# psoc4hvpaspm10 register map
Vendor: Infineon Technologies; Series: PSOC4HVPASPM10; File version: 1.0
CPU: CM0PLUS r0p1, little endian, MPU, no FPU, VTOR, 2 interrupt priority bits, 32 interrupts
Registers are 32-bit, read-write, reset 0x0 unless marked. A register's access mark holds for its fields unless they carry their own. Offsets are from the block's base; [hi:lo] are bit positions; lines under a group give offsets from that group; {n}, {i} and the like mark numbered series; 'fields as' and 'values as' point back to an identical list; <NAME> marks a mode.

## PACSS (part 2 of 2) — Programmable Analog Channel Sub-System
Base 0x40300000
{0x40000+0x10000*i} ACHAN[{i}] (i=0..1) group — Analog Channel Configuration
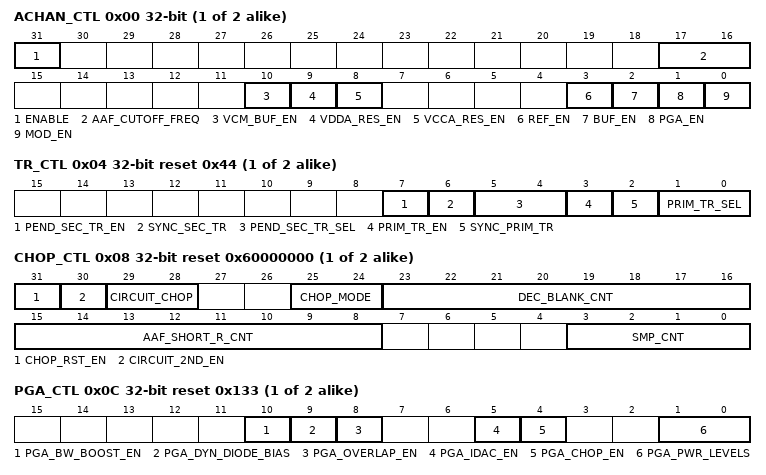
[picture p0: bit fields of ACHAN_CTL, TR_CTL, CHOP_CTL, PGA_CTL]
  0x00 ACHAN_CTL — Analog Channel Control
    [31] ENABLE — Analog Channel Enable
    [17:16] AAF_CUTOFF_FREQ
    [10] VCM_BUF_EN — VCM Buffer Enable VCM_BUF is the buffer that provides the common mode for the differential amplifiers in the modulator. It also provides input common mode to the sampling capacitor of the integrators.
    [9] VDDA_RES_EN — VDDA Resistor Reference Enable This is one of the reference options for the modulator. It is meant to be used for diagnostics.
    [8] VCCA_RES_EN — VCCA Resistor Reference Enable This is one of the options for the VCM voltage. The default is 0.8V from HPBGR. This is added for risk-mitigation.
    [3] REF_EN — Reference Enable It enables the *_SEL controls in the REF_CTL registers, which allows switch closure for the reference selection.
    [2] BUF_EN — Buffer Enable Enables the buffer, when disabled all buffer controls from BUF_CTL are disabled.
    [1] PGA_EN — Programmable Gain Amplifier Enable (also enables VNEG Pump)
    [0] MOD_EN — Modulator Enable (also enables INMUX)
  0x04 TR_CTL reset 0x44 — Trigger Control for Sequencer
    [7] PEND_SEC_TR_EN — Secondary Trigger Enable (enables HW triggers) if disabled, conversion can still be pended via user SW
    [6] SYNC_SEC_TR — Synchronize Secondary Trigger 0 - bypass clock domain synchronization of the trigger signal. 1 - synchronize the trigger signal to the DSM clock domain, if needed an edge detect is done in the peripheral clock domain. Only applicable to HW triggers
    [5:4] PEND_SEC_TR_SEL — Select for Trigger that pends secondary digital channels linked to this analog channel to convert on the next primary trigger. 0 - select HW tr_start[0] 1 - select HW tr_start[1] 2 - select HW tr_start[2] 3 - select HW tr_start[3] Only applicable to HW triggers
    [3] PRIM_TR_EN — Primary Trigger Enable (enables HW triggers) if disabled, conversion can still be started via user SW
    [2] SYNC_PRIM_TR — Synchronize Primary Trigger 0 - bypass clock domain synchronization of the trigger signal. 1 - synchronize the trigger signal to the DSM clock domain, if needed an edge detect is done in the peripheral clock domain. Only applicable to HW triggers
    [1:0] PRIM_TR_SEL — Select for Primary Trigger. Triggers starts conversion on all primary digital channels linked to this analog channel. 0 - select HW tr_start[0] 1 - select HW tr_start[1] 2 - select HW tr_start[2] 3 - select HW tr_start[3] Only applicable to HW triggers
  0x08 CHOP_CTL reset 0x60000000 — Chopping Control for Sequencer
    [31] CHOP_RST_EN
    [30] CIRCUIT_2ND_EN — 2nd Stage Circuit Chopping Enable Enables Circuit Chopping on the 2nd integrator in the modulator
    [29:28] CIRCUIT_CHOP — Circuit Chopping 0 - Off 1 - Disconnect AAF (SW1) for 1 DSM clock cycle after fchop clock edge 2 - Disconnect AAF (SW1) for 2 DSM clock cycle after fchop clock edge 3 - Disconnect AAF (SW1) for 4 DSM clock cycle after fchop clock edge Circuit chopping differs from the other fields in this register, it has no interaction with the modbit. When enabled it disconnects the AAF for the set number of clock cycles after a fchop clock edge.
    [25:24] CHOP_MODE — Chopping Mode 00 - OFF: Buffer Cross Chopping Disabled 01 - Not supported 11 - Buffer Cross Chopping Enabled 10 - Not supported Buffer cross chopping is on the input and output of the buffer using the modbit. This mode toggles the modbit when the SMP_CNT value is reached. Buffer cross chopping is only functional in the configurations where ACHAN0 is only mapped to DCHAN0, or ACHAN1 (if present) is only mapped to DCHAN1 (if present).
    [23:16] DEC_BLANK_CNT — Decimator Blanking Count Number of DSM clock cycles (DEC_BLANK_CNT) where the decimator will be disconnected from the modulator output stream, and connected to a circular FIFO of the last 32 data values after the modbit toggles
    [15:8] AAF_SHORT_R_CNT — Anti-Aliasing Filter Short Resistor Count Number of DSM clock cycles (AAF_SHORT_CNT) to short the AAF resistor after a toggle of the modbit.
    [3:0] SMP_CNT — Chopping Sample Count Number of samples to count before toggling modbit. (SMP_CNT+1). The samples counted rely only on the DR value set in DEC_CTL or SEQ_CTL. Depending on which one the Decimator is using.
  0x0C PGA_CTL reset 0x133 — Programmable Gain Amplifier Control
    [10] PGA_BW_BOOST_EN — TBD - Currently not used
    [9] PGA_DYN_DIODE_BIAS — TBD - Currently not used
    [8] PGA_OVERLAP_EN — PGA Overlap Enable Enable overlapping for the PGA chopping clocks. When disabled, PGA chopping clocks are non-overlapping
    [5] PGA_IDAC_EN — IDAC Enable
    [4] PGA_CHOP_EN — Chopping Enable
    [1:0] PGA_PWR_LEVELS — PGA Power Levels 00 - 39 percent Power Mode 01 - 58 percent Power Mode 10 - 78 percent Power Mode 11 - 100 percent Power Mode
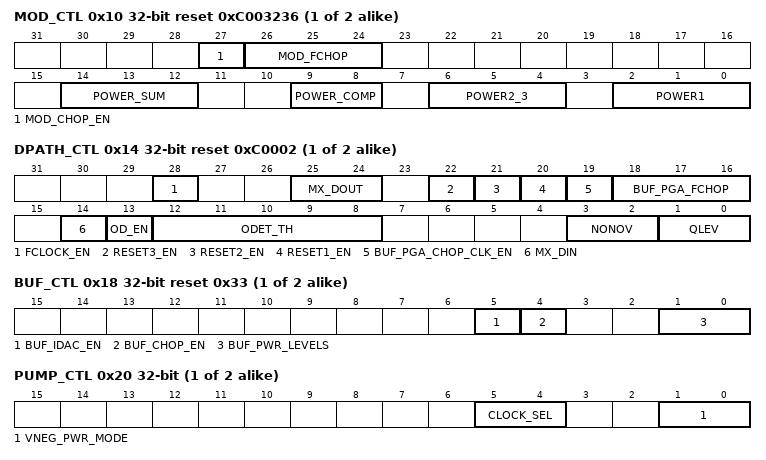
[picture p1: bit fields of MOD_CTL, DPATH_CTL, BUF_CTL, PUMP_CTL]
  0x10 MOD_CTL reset 0xC003236 — Modulator Control
    [27] MOD_CHOP_EN — Modulator Chopping Enable
    [26:24] MOD_FCHOP — Modulator Chopping Clock Frequency Selection
      0=FCLOCKDIV2 (chopping frequency is Fclock/2); 1=FCLOCKDIV4 (chopping frequency is Fclock/4); 2=FCLOCKDIV8 (chopping frequency is Fclock/8); 3=FCLOCKDIV16 (chopping frequency is Fclock/16); 4=FCLOCKDIV32 (chopping frequency is Fclock/32); 5=FCLOCKDIV64 (chopping frequency is Fclock/64); 6=FCLOCKDIV128 (chopping frequency is Fclock/128); 7=FCLOCKDIV256 (chopping frequency is Fclock/256)
    [14:12] POWER_SUM — The power control for the summer block
      0=POWER_SUM_53uA (75 percent Power Mode); 1=POWER_SUM_58uA (81 percent Power Mode); 2=POWER_SUM_67uA (94 percent Power Mode); 3=POWER_SUM_71uA (100 percent Power Mode); 4=POWER_SUM_105uA (150 percent Power Mode); 5=POWER_SUM_71uA_2 (N/A); 6=POWER_SUM_71uA_3 (N/A); 7=POWER_SUM_71uA_4 (N/A)
    [9:8] POWER_COMP — The power control for the quantizer block
      0=50 percent Power Mode; 1=75 percent Power Mode; 2=100 percent Power Mode; 3=200 percent Power Mode
    [6:4] POWER2_3 — The power control for the second and third integrator stages
      0=POWER2_3_97uA (75 percent Power Mode); 1=POWER2_3_106uA (81 percent Power Mode); 2=POWER2_3_122uA (94 percent Power Mode); 3=POWER2_3_130uA (100 percent Power Mode); 4=POWER2_3_193uA (150 percent Power Mode); 5=POWER2_3_130uA_2 (100 percent Power Mode); 6=POWER2_3_130uA_3 (100 percent Power Mode); 7=POWER2_3_130uA_4 (100 percent Power Mode)
    [2:0] POWER1 — First stage Opamp power level control
      0=POWER1_44uA (10 percent Power Mode); 1=POWER1_135uA (31 percent Power Mode); 2=POWER1_190uA (44 percent Power Mode); 3=POWER1_271uA (63 percent Power Mode); 4=POWER1_325uA (75 percent Power Mode); 5=POWER1_380uA (88 percent Power Mode); 6=POWER1_433uA (100 percent Power Mode); 7=POWER1_652uA (150 percent Power Mode)
  0x14 DPATH_CTL reset 0xC0002 — Datapath Control
    [28] FCLOCK_EN — Modulator Clock Enable (FCLOCK) By default the modulator clock only runs when converting a sample. Setting FCLOCK_CLK_EN=1 makes FCLOCK free running.
    [25:24] MX_DOUT — Select the DSM data routed to the dbg_io output: 2'h0: none 2'h1: dbg_io[5:0] = {modrst, clk_dsm_ana, dout2scomp[3:0]} 2'h2: dbg_io[5:0] = {ovdcause, ovdflag, agc_gain_lvl[3:0]} 2'h3: dbg_io[5:0] = {modrst, clk_dsm_ana, agc_gain_lvl[3:0]}
    [22] RESET3_EN — Allow third stage integrating capacitance to be reset. If enabled this reset is triggered by an overload detection
    [21] RESET2_EN — Allow second stage integrating capacitance to be reset. If enabled this reset is triggered by an overload detection
    [20] RESET1_EN — Allow first stage integrating capacitance to be reset. If enabled this reset is triggered by an overload detection
    [19] BUF_PGA_CHOP_CLK_EN — Buffer and PGA Chopping Clock enable for Buffer and PGA This bit should be set to 1 by SW in the default use case.
    [18:16] BUF_PGA_FCHOP — Chopping Clock Frequency selection for Buffer and PGA
      0=FCLOCKDIV2 (Fclock/2); 1=FCLOCKDIV4 (Fclock/4); 2=FCLOCKDIV8 (Fclock/8); 3=FCLOCKDIV16 (Fclock/16); 4=FCLOCKDIV32 (Fclock/32); 5=FCLOCKDIV64 (Fclock/64); 6=FCLOCKDIV128 (Fclock/128); 7=FCLOCKDIV256 (Fclock/256)
    [14] MX_DIN — Select the data source of the Decimator input : 0: modulator data is selected as input to decimator 1: dbg_io[3:0] is selected as the input to the decimator. In this mode dbg_io[5:4] are outputs. dbg_io[5:4]={modrst, clk_dsm_ana} Previously named DPMODE
    [13] OD_EN — Overload Detect Enable
    [12:8] ODET_TH — Overload detection threshold. If the number of continuous 1s or 0s coming out of quantizer exceeds this number, the overload detection flag is set
    [3:2] NONOV — Non-Overlap delay of clock phases 2'h0: low (1.57ns, typ) 2'h1: medium (2.54ns, typ) 2'h2: high (6.47ns, typ) 2'h3: very high (9.91ns, typ) Default is low, other settings are for risk mitigation
    [1:0] QLEV
  0x18 BUF_CTL reset 0x33 — Buffer Control
    [5] BUF_IDAC_EN — Buffer IDAC enable
    [4] BUF_CHOP_EN — Buffer chopping enable
    [1:0] BUF_PWR_LEVELS — Buffer Power Levels 00 - 32 percent Power Mode 01 - 55 percent Power Mode 10 - 78 percent Power Mode 11 - 100 percent Power Mode
  0x20 PUMP_CTL — Pump Control
    [5:4] CLOCK_SEL — Negative Pump Clock selection The negative pump requires a 24 MHz clock For bit decode use the following: 00: pump clock sourced by clk_pump/2, use if clk_pump is set to 48MHz 01: pump clock sourced by clk_pump/1, use if clk_pump is set to 24 MHz 10: pump clock sourced by clk_hf/2, use if clk_hf is set to 48 MHz 11: pump clock sourced by clk_hf/1, use if clk_hf is set to 24 MHz
    [1:0] VNEG_PWR_MODE — Negative pump power mode. Trim for risk mitigation, not intended for customer use.
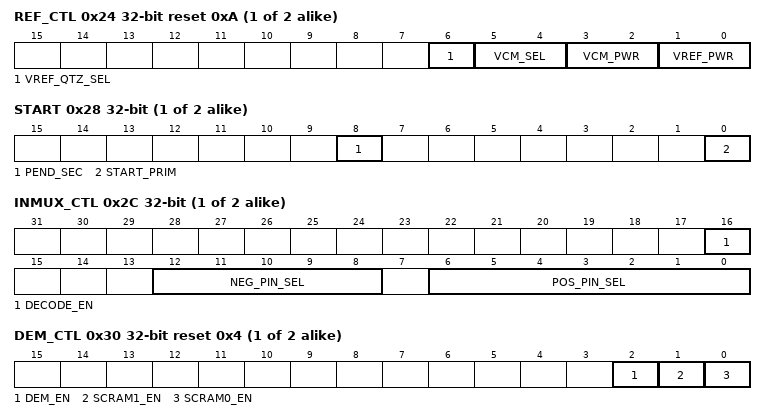
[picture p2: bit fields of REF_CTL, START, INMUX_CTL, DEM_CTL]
  0x24 REF_CTL reset 0xA — Reference Control
    [6] VREF_QTZ_SEL — VREF_QTZ selection 0 - VREFH CDAC 1 - VCCA_KELVIN
    [5:4] VCM_SEL
    [3:2] VCM_PWR — Power Control for the Voltage Common Mode Buffer for the Sigma Delta ADC
      0=VCM_18uA (VCM Buffer is operating in Low Power (18 uA) mode); 1=VCM_28uA (VCM Buffer is operating in Medium Power (28 uA) mode); 2=VCM_55uA (VCM Buffer is operating in High Power (55 uA) mode); 3=VCM_114uA (VCM Buffer is operating in Turbo Power (114 uA) mode)
    [1:0] VREF_PWR — Power control for the voltage reference buffer for the sigma delta ADC
      0=VREF_26uA (VREF Buffer is operating in Low Power (26 uA) mode); 1=VREF_32uA (VREF Buffer is operating in Medium Power (32 uA) mode); 2=VREF_118uA (VREF Buffer is operating in High Power (118 uA) mode); 3=VREF_232uA (VREF Buffer is operating in Turbo Power (232 uA) mode)
  0x28 START — Start Conversion
    [8] PEND_SEC write-1-sets — Pend Secondary Conversion (FW Trigger) A write of 1 to this bit pends a secondary conversion. This bit is cleared after the next primary conversion completes.
    [0] START_PRIM write-1-sets — Start Primary Conversion (FW Trigger) . A write of 1 to this bit starts a primary conversion. This bit is cleared once the conversion is started. A write of 1 while the sequencer is busy is ignored and the FWT_COLLISION interrupt is set for the digital channels assigned to this sequencer.
  0x2C INMUX_CTL — INMUX Control
    [16] DECODE_EN — Enables Decode Logic to close switches. This must be set to '1' allow usage of POS_PIN_SEL and NEG_PIN_SEL. If set to '0' all switches in the INMUX will be open. This register is only applicable when SWITCH_SQ_CTL.INMUX=0
    [12:8] NEG_PIN_SEL — Negative Pin Select This register is only functional when the sequencer control of the INMUX is disabled. See SWITCH_SQ_CTL.INMUX. This register is the manual (non-sequencer) configuration of INMUX negative pin selection.
      0=NEG_PIN_SEL_VSSA (0x00 - vssa); 8=NEG_PIN_SEL_VSSA_K0 (0x08 - vssa_k0, unused (floating)); 9=NEG_PIN_SEL_VSSA_K1 (0x09 - vssa_k1, vrefl); 10=NEG_PIN_SEL_VSSA_K2 (0x0A - vssa_k2, srss_vss); 11=NEG_PIN_SEL_VSSA_K3 (0x0B - vssa_k3, vdiv_ret); 12=NEG_PIN_SEL_VSSA_K4 (0x0C - vssa_k4, vts_ret); 13=NEG_PIN_SEL_VSSA_K5 (0x0D - vssa_k5, vtint_ret); 14=NEG_PIN_SEL_VSSA_K6 (0x0E - vssa_k6, gpio0); 15=NEG_PIN_SEL_VSSA_K7 (0x0F - vssa_k7, gpio2); 16=NEG_PIN_SEL_RSL0 (0x10 - rsl0); 24=NEG_PIN_SEL_RSL1 (0x18 - rsl1)
    [6:0] POS_PIN_SEL — Positive Pin Select This register is only functional when the sequencer control of the INMUX is disabled. See SWITCH_SQ_CTL.INMUX. This register is the manual (non-sequencer) configuration of INMUX positive pin selection.
  0x30 DEM_CTL reset 0x4 — Dynamic Element Matching Control
    [2] DEM_EN — Enable DEM Bi-directional Data Weighted Averaging (DWA) based Dynamic Element Matching (DEM) scheme for mismatch cancellation. Bi-directional DWA alters the direction of pointers used for rotation every cycle for avoiding repetition pattern of the DWA for low value DC inputs. DWA mode: SCRAM0_EN=0, SCRAM1_EN=0 Alternate DWA mode (not preferred): SCRAM0_EN=1, SCRAM1_EN=0 Bi-DWA mode: SCRAM0_EN=0, SCRAM1_EN=1 Not used: SCRAM0_EN=1, SCRAM1_EN=1
    [1] SCRAM1_EN — Enable Scrambler 1 Also known as EN_BIDWA
    [0] SCRAM0_EN — Enable Scrambler 0 Also known as EN_ADWA
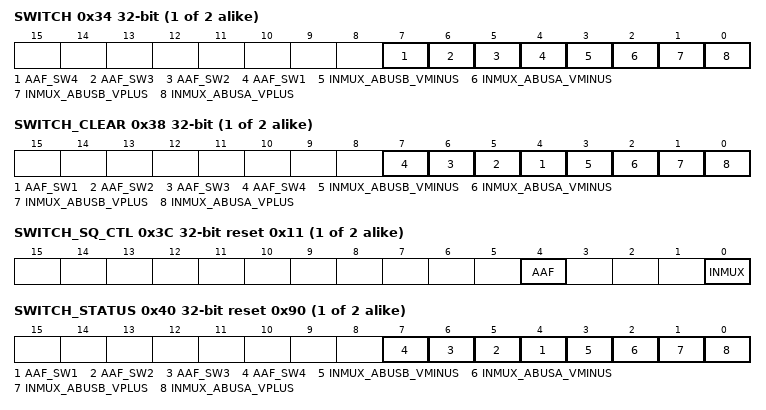
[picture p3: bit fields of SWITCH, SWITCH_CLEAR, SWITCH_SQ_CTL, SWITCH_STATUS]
  0x34 SWITCH — Firmware Switch Control
    [7] AAF_SW4 write-1-sets — Firmware control: 0=open, 1=close AAF switch 4. Write with '1' to set bit. This switch can only be closed via this register if SWITCH_SQ_CTL.AAF=0
    [6] AAF_SW3 write-1-sets — Firmware control: 0=open, 1=close AAF switch 3. Write with '1' to set bit. This switch can only be closed via this register if SWITCH_SQ_CTL.AAF=0.
    [5] AAF_SW2 write-1-sets — Firmware control: 0=open, 1=close AAF switch 2. Write with '1' to set bit. This switch can only be closed via this register if SWITCH_SQ_CTL.AAF=0
    [4] AAF_SW1 write-1-sets — Firmware control: 0=open, 1=close AAF switch 1. Write with '1' to set bit. This switch can only be closed via this register if SWITCH_SQ_CTL.AAF=0
    [3] INMUX_ABUSB_VMINUS write-1-sets — Firmware control: 0=open, 1=close switch between VMINUS and AMUXBUSB. Write with '1' to set bit. This switch can be closed while the sequencer is controls the INMUX pin selection
    [2] INMUX_ABUSA_VMINUS write-1-sets — Firmware control: 0=open, 1=close switch between VMINUS and AMUXBUSA output. Write with '1' to set bit. This switch can be closed while the sequencer is controls the INMUX pin selection
    [1] INMUX_ABUSB_VPLUS write-1-sets — Firmware control: 0=open, 1=close switch between VPLUS and AMUXBUSB. Write with '1' to set bit. This switch can be closed while the sequencer is controls the INMUX pin selection
    [0] INMUX_ABUSA_VPLUS write-1-sets — Firmware control: 0=open, 1=close switch between VPLUS and AMUXBUSA output. Write with '1' to set bit. This switch can be closed while the sequencer is controls the INMUX pin selection
  0x38 SWITCH_CLEAR — Firmware Switch Control Clear
    [n+3] AAF_SW{n} write-1-clears (n=1..4) — Write '1' to clear corresponding bit in the SWITCH register
    [3] INMUX_ABUSB_VMINUS write-1-clears — Write '1' to clear corresponding bit in the SWITCH register
    [2] INMUX_ABUSA_VMINUS write-1-clears — Write '1' to clear corresponding bit in the SWITCH register
    [1] INMUX_ABUSB_VPLUS write-1-clears — Write '1' to clear corresponding bit in the SWITCH register
    [0] INMUX_ABUSA_VPLUS write-1-clears — Write '1' to clear corresponding bit in the SWITCH register
  0x3C SWITCH_SQ_CTL reset 0x11 — Switch Sequencer Control
    [4] AAF — Allow sequencer control for the provided switches
    [0] INMUX — Allow sequencer control for the provided switches
  0x40 SWITCH_STATUS ro reset 0x90
    [n+3] AAF_SW{n} (n=1..4) — switch status of corresponding bit in the SWITCH register
    [3] INMUX_ABUSB_VMINUS — switch status of corresponding bit in the SWITCH register
    [2] INMUX_ABUSA_VMINUS — switch status of corresponding bit in the SWITCH register
    [1] INMUX_ABUSB_VPLUS — switch status of corresponding bit in the SWITCH register
    [0] INMUX_ABUSA_VPLUS — switch status of corresponding bit in the SWITCH register
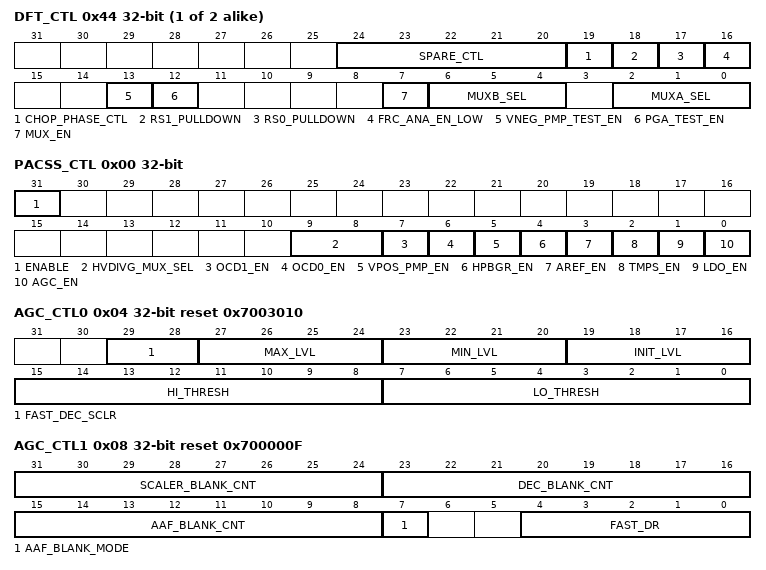
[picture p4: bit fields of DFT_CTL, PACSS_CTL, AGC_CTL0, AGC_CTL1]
  0x44 DFT_CTL — DFT Control Register
    [24:20] SPARE_CTL — Spare MMIO Controls for analog
    [19] CHOP_PHASE_CTL — Circuit chopping phase control. Inverts circuit chopping phase
    [18] RS1_PULLDOWN — RS1 Pull-down. Enables pull down on RSH1/RSL1 input pair for offset calibration.
    [17] RS0_PULLDOWN — RS0 Pull-down. Enables pull down on RSH0/RSL0 input pair for offset calibration.
    [16] FRC_ANA_EN_LOW — Force global analog enable low (enable_scanoff_hv) to test for any SA1 faults on the level-shifter enables.
    [13] VNEG_PMP_TEST_EN — Negative Pump Test Enable
    [12] PGA_TEST_EN — PGA Test Mode
    [7] MUX_EN — DFT MUX Enable
    [6:4] MUXB_SEL — DFT MUX Selection for AMUXBUSB
      0=VCCA_DSM_DFT (dft_out = vcca_dsm_dft); 1=REFOUT (dft_out = refout); 2=VREF_QTZ (dft_out = vref_qtz); 3=AAF_IN_N (dft_out = aaf_in_n); 4=IREF_2P4U (dft_out = iref_2p4u - current source of buffer top amp cascode device); 5=BUFFIN_VMINUS (dft_out = buffin_vminus); 6=BUFFIN_VPLUS (dft_out = buffin_vplus); 7=BUFOUT_VMINUS (dft_out = bufout_vminus)
    [2:0] MUXA_SEL — DFT MUX Selection for AMUXBUSA
      0=VCCA_DSM_DFT_KELVIN (dft_out = vcca_dsm_dft_kelvin); 1=VCM (dft_out = vcm); 2=VREF_DAC (dft_out = vref_dac); 3=AAF_IN_P (dft_out = aaf_in_p); 4=IREF_4P8U (dft_out = iref_4p8u - current source of PGA top amp cascode device); 5=BUFFIN_VPLUS (dft_out = buffin_vplus); 6=BUFFIN_VMINUS (dft_out = buffin_vminus); 7=BUFOUT_VPLUS (dft_out = bufout_vplus)
  0x48 DFT_STATUS ro
    [0] OBSVR_LS_OUT — Observation point of level-shifters output. Used for detection of SA1 faults on the level-shifter enables. The read back value of this register changes based on the configuration and trims of the ACHAN and PACSS_MMIO registers.
  0xFF00 TRIM_PGA0_CTL — PGA Trim 0 (lock protected)
    [5:0] OFST_P — Offset Plus Trim
  0xFF04 TRIM_PGA1_CTL — PGA Trim 1 (lock protected)
    [5:0] OFST_SLOPE_P — Offset Slope Plus Trim
  0xFF08 TRIM_PGA2_CTL — PGA Trim 2 (lock protected)
    [5:0] OFST_M — Offset Minus Trim
  0xFF0C TRIM_PGA3_CTL — PGA Trim 3 (lock protected)
    [5:0] OFST_SLOPE_M — Offset Slope Minus Trim
  0xFF10 TRIM_PGA4_CTL reset 0x4 — PGA Trim 4 (lock protected)
    [2:0] CM — Common Mode (Output Range) Trim
  0xFF14 TRIM_BUF0_CTL — Buffer Trim 0 (lock protected)
    [5:0] OFST_P — Offset Plus Trim
  0xFF18 TRIM_BUF1_CTL — Buffer Trim 1 (lock protected)
    [5:0] OFST_PTAT_P — Offset PTAT Plus Trim
  0xFF1C TRIM_BUF2_CTL — Buffer Trim 2 (lock protected)
    [5:0] OFST_M — Offset Minus Trim
  0xFF20 TRIM_BUF3_CTL — Buffer Trim 3 (lock protected)
    [5:0] OFST_PTAT_M — Offset PTAT Minus Trim
0xF0000 MMIO group — PACSS Global MMIO
  0x00 PACSS_CTL — Precision Analog Channel Control
    [31] ENABLE — Global Enable
    [9:8] HVDIVG_MUX_SEL — High Voltage Divider Ground Reference Mux Select 0 - Select VSSA 1 - Select VSSA 2 - Select RSH[0] 3 - Select RSL[0] This field is not applicable if VDIAG pin is not a package pin, in which case the selection is forced to VSSA regardless of how this field is set.
    [7] OCD1_EN — Over Current Detection 1 Enable
    [6] OCD0_EN — Over Current Detection 0 Enable
    [5] VPOS_PMP_EN — Positive Pump Enable
    [4] HPBGR_EN — High Precision Bandgap Reference Enable
    [3] AREF_EN — AREF Enable
    [2] TMPS_EN — Temperature Sensor Enable
    [1] LDO_EN — Low Dropout Regulator Enable Enables modulator voltage supply
    [0] AGC_EN — Auto-Gain Correction Enable
  0x04 AGC_CTL0 reset 0x7003010 — Auto-Gain Correction Control 0
    [29:28] FAST_DEC_SCLR — Fast Decimator Scaler Used to apply digital gain to output of the AGC's fast decimator. Intended to be used when digital gain is applied to the system via moving sum. 0 : FAST_DEC_RESULT = RESULT 1 : FAST_DEC_RESULT = RESULT << 1 2 : FAST_DEC_RESULT = RESULT << 2 3 : FAST_DEC_RESULT = RESULT << 3
    [27:24] MAX_LVL — Maximum Gain level The maximum gain level that the AGC is allowed to reach when incrementing Acceptable values are 0 - 9, but MIN_LVL <= INIT_LVL <= MAX_LVL
    [23:20] MIN_LVL — Minimum Gain Level The minimum gain level the AGC is allowed to reach when decrementing. Acceptable values are 0 - 9, but MIN_LVL <= INIT_LVL <= MAX_LVL
    [19:16] INIT_LVL — Initial Gain level The gain level that the AGC is initialized to once a conversion starts. Acceptable values are 0 - 9.
    [15:8] HI_THRESH — High Threshold value Magnitude of high threshold value. This is an absolute value comparison. If the fast decimator result is higher than this threshold value, the gain level will be decremented. Gain levels must be configured from lowest to highest gain. modulator output ranges from -4 to 4. The max value will be 4* (FAST_DR+1) Based on default values: 4*16 = 64, default is 75 percent (48=0x30) Ex: set 0x64 to set to -100 (decimal) or 100 (decimal)
    [7:0] LO_THRESH — Low Threshold value Magnitude of lower threshold value. This is an absolute value comparison. If the fast decimator result is lower than this threshold value, the gain level will be incremented. Gain levels must be configured from lowest to highest gain. modulator output ranges from -4 to 4. The max value will be 4* (FAST_DR+1) Based on default values: 4*16 = 64, default is 25 percent (16=0x10) Ex: set to 0x20 to set to -32 (decimal) or 32 (decimal)
  0x08 AGC_CTL1 reset 0x700000F — Auto-Gain Correction Control 1
    [31:24] SCALER_BLANK_CNT — Scaler Blank Count Number of DSM clock cycles (SCALER_BLANKT_CNT) where the gain scaler of next gain level will be delayed after a gain level change. The scaler will use its previous value until this count value is reached.
    [23:16] DEC_BLANK_CNT — Decimator Blank Count Number of DSM clock cycles (DEC_BLANK_CNT) where the decimator will be disconnected from the modulator output stream, and connected to a circular FIFO of the last 32 data values after a gain level change.
    [15:8] AAF_BLANK_CNT — AAF Blank Count Number of DSM clock cycles (AAF_BLANK_CNT) where the AAF will either be shorted or disconnected after a gain level change.
    [7] AAF_BLANK_MODE — Anti-Aliasing Filter (AAF) Blanking Mode 0 - Short AAF resistor (close SW2) 1 - Bypass AAF (open SW1) Shorting the AAF reduces the settling time
    [4:0] FAST_DR — Fast Decimator Decimation Ratio (FAST_DR+1) sets the decimation ratio for the AGC's Fast Decimator The fast decimator will run continuously with this FAST_DR value while the DCHAN0 decimator is running.
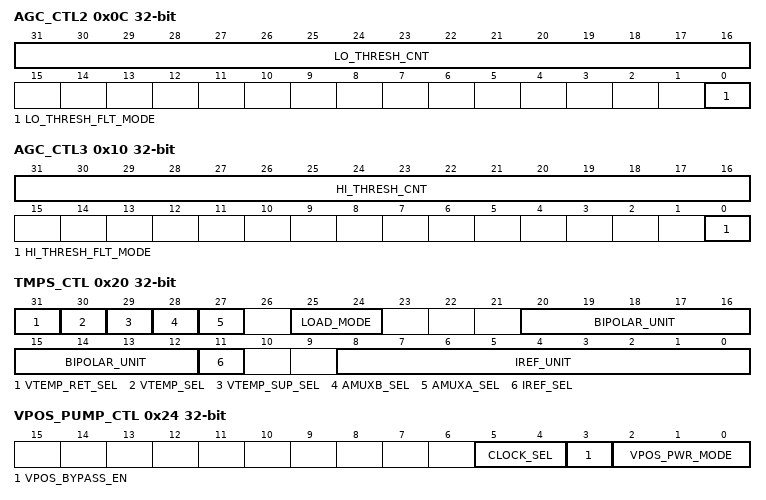
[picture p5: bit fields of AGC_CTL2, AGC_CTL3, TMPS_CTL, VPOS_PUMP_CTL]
  0x0C AGC_CTL2 — Auto-Gain Correction Control 2
    [31:16] LO_THRESH_CNT — Low Threshold Filter Counter LO_THRESH_CNT + 1, is the count value used for filtering the next gain level change.
    [0] LO_THRESH_FLT_MODE — Low Threshold Filter Mode 0 - counter mode 1 - integrator mode
  0x10 AGC_CTL3 — Auto-Gain Correction Control 3
    [31:16] HI_THRESH_CNT — High Threshold Filter Counter HI_THRESH_CNT + 1, is the count value used for filtering the next gain level change.
    [0] HI_THRESH_FLT_MODE — High Threshold Filter Mode 0 - counter mode 1 - integrator mode
  0x20 TMPS_CTL — Temperature Sensor Control
    [31] VTEMP_RET_SEL — Connect VTEMP_RET pin to the vssa_kelvin of the BJTs and resistor.
    [30] VTEMP_SEL — Connect VTEMP pin to vbe/vres output voltage.
    [29] VTEMP_SUP_SEL — Select external current source to bias the BJTs or Resistor.
    [28] AMUXB_SEL — Select amuxbus_b to be connected to temp sensor vbe/vres output.
    [27] AMUXA_SEL — Select amuxbus_a as a current source for biasing BJTs or Resistor
    [25:24] LOAD_MODE
    [20:12] BIPOLAR_UNIT — Number of bipolar transistors, between 0 (all switches open) and 9 Each bit set of BIPOLAR_UNIT, adds a BIPOLAR transistors Only applicable for PNP and NPN load modes
    [11] IREF_SEL — Temperature Sensor Current Reference Select Select between SRSS and AREF current reference 0 - selects AREF as current reference source 1 - selects SRSS as current reference source
    [8:0] IREF_UNIT — Number of units, between 0 (all switches open) and 9 IREF current = 9.6uA * (# of bits set) Each bit set of IREF_UNIT adds a multiple of 9.6uA.
  0x24 VPOS_PUMP_CTL — Positive Pump Control
    [5:4] CLOCK_SEL — Positive Pump Clock selection The positive pump requires a 24 MHz clock For bit decode use the following: 00: pump clock sourced by clk_pump/2, use if clk_pump is set to 48MHz 01: pump clock sourced by clk_pump/1, use if clk_pump is set to 24 MHz 10: pump clock sourced by clk_hf/2, use if clk_hf is set to 48 MHz 11: pump clock sourced by clk_hf/1, use if clk_hf is set to 24 MHz
    [3] VPOS_BYPASS_EN
    [2:0] VPOS_PWR_MODE
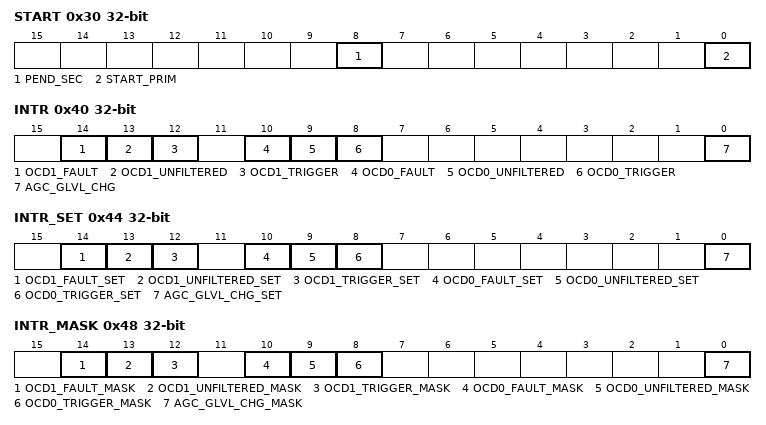
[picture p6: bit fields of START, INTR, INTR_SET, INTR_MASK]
  0x30 START — Start Conversion
    [8] PEND_SEC write-1-sets — Pend Secondary Conversion (FW Trigger) A write of 1 to this bit pends a secondary conversion. This bit is cleared after the next primary conversion completes.
    [0] START_PRIM write-1-sets — Start Primary Conversion (FW Trigger) . A write of 1 to this bit starts a primary conversion on both sequencers simultaneously. This bit is cleared once the conversion is started. A write of 1 while the sequencer(s) is busy is ignored and the FWT_COLLISION interrupt is set for the digital channels assigned to sequencer(s) that are busy.
  0x40 INTR — System Interrupt request register
    [14] OCD1_FAULT write-1-clears — Over Current Detection 1 Fault Interrupt Hardware sets this interrupt when there is a fault in the Over Current Detection Glitch Filter as defined in tables 4 and 5 in BROS . Write with '1' to clear bit.
    [13] OCD1_UNFILTERED write-1-clears — Over Current Detection 1 Unfiltered Interrupt Hardware sets this interrupt when either ocd_pos_out or ocd_neg_out is asserted. Write with '1' to clear bit.
    [12] OCD1_TRIGGER write-1-clears — Over Current Detection 1 Trigger Interrupt Hardware sets this interrupt when an over current detection trigger occurs. Write with '1' to clear bit.
    [10] OCD0_FAULT write-1-clears — Over Current Detection 0 Fault Interrupt Hardware sets this interrupt when there is a fault in the Over Current Detection Glitch Filter as defined in tables 4 and 5 in BROS . Write with '1' to clear bit.
    [9] OCD0_UNFILTERED write-1-clears — Over Current Detection 0 Unfiltered Interrupt Hardware sets this interrupt when either ocd_pos_out or ocd_neg_out is asserted. Write with '1' to clear bit.
    [8] OCD0_TRIGGER write-1-clears — Over Current Detection 0 Trigger Interrupt Hardware sets this interrupt when an over current detection trigger occurs. Write with '1' to clear bit.
    [0] AGC_GLVL_CHG write-1-clears — AGC Gain Level Change Interrupt Hardware sets this interrupt when a gain level change occurs. Write with '1' to clear bit.
  0x44 INTR_SET — System Interrupt set request register
    [14] OCD1_FAULT_SET write-1-sets — Write with '1' to set corresponding bit in interrupt request register.
    [13] OCD1_UNFILTERED_SET write-1-sets — Write with '1' to set corresponding bit in interrupt request register.
    [12] OCD1_TRIGGER_SET write-1-sets — Write with '1' to set corresponding bit in interrupt request register.
    [10] OCD0_FAULT_SET write-1-sets — Write with '1' to set corresponding bit in interrupt request register.
    [9] OCD0_UNFILTERED_SET write-1-sets — Write with '1' to set corresponding bit in interrupt request register.
    [8] OCD0_TRIGGER_SET write-1-sets — Write with '1' to set corresponding bit in interrupt request register.
    [0] AGC_GLVL_CHG_SET write-1-sets — Write with '1' to set corresponding bit in interrupt request register.
  0x48 INTR_MASK — System Interrupt mask register
    [14] OCD1_FAULT_MASK — Mask bit for corresponding bit in interrupt request register.
    [13] OCD1_UNFILTERED_MASK — Mask bit for corresponding bit in interrupt request register.
    [12] OCD1_TRIGGER_MASK — Mask bit for corresponding bit in interrupt request register.
    [10] OCD0_FAULT_MASK — Mask bit for corresponding bit in interrupt request register.
    [9] OCD0_UNFILTERED_MASK — Mask bit for corresponding bit in interrupt request register.
    [8] OCD0_TRIGGER_MASK — Mask bit for corresponding bit in interrupt request register.
    [0] AGC_GLVL_CHG_MASK — Mask bit for corresponding bit in interrupt request register.
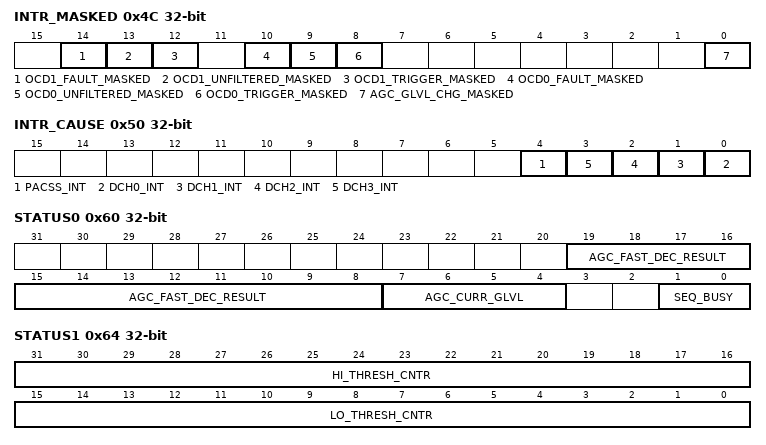
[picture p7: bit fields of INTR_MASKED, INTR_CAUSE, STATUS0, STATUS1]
  0x4C INTR_MASKED ro — System Interrupt masked request register
    [14] OCD1_FAULT_MASKED — Logical and of corresponding request and mask bits.
    [13] OCD1_UNFILTERED_MASKED — Logical and of corresponding request and mask bits.
    [12] OCD1_TRIGGER_MASKED — Logical and of corresponding request and mask bits.
    [10] OCD0_FAULT_MASKED — Logical and of corresponding request and mask bits.
    [9] OCD0_UNFILTERED_MASKED — Logical and of corresponding request and mask bits.
    [8] OCD0_TRIGGER_MASKED — Logical and of corresponding request and mask bits.
    [0] AGC_GLVL_CHG_MASKED — Logical and of corresponding request and mask bits.
  0x50 INTR_CAUSE ro — Interrupt Cause Register
    [4] PACSS_INT — System (PACSS_MMIO) Interrupt Pending
    [n] DCH{n}_INT (n=0..3) — Digital Channel {n} Interrupt Pending
  0x60 STATUS0 ro — Status Register 0
    [19:8] AGC_FAST_DEC_RESULT — AGC Fast Decimator Result
    [7:4] AGC_CURR_GLVL — AGC Current gain level
    [1:0] SEQ_BUSY — Sequencer Busy, bit per analog channel
  0x64 STATUS1 ro — Status Register 1
    [31:16] HI_THRESH_CNTR — Status of High threshold counter
    [15:0] LO_THRESH_CNTR — Status of Low threshold counter
  {0x100+0x10*j} GAINLVL_STRUCT[{j}] (j=0..9) group — Gain Level Configuration
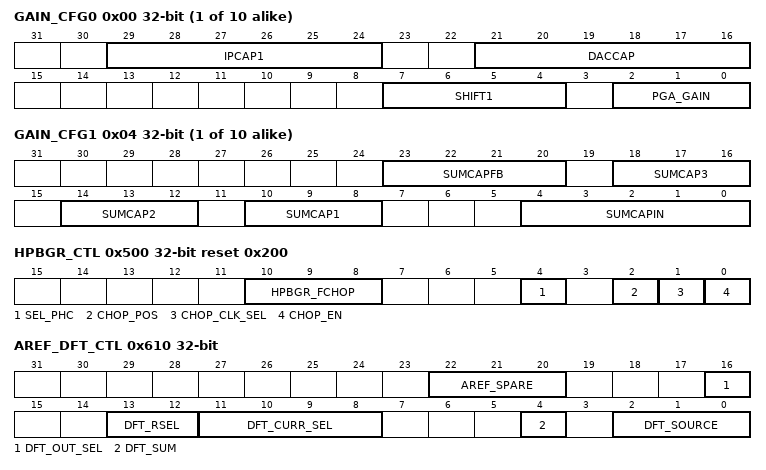
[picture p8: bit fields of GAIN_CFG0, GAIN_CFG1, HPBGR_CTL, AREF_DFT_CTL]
    0x00 GAIN_CFG0 — Gain configuration register 0
      [29:24] IPCAP1 — Binary weighted first stage integrating capacitance
        0=IPCAP1_min (Min Value = 100 fF); 63=IPCAP1_max (Max Value = 6.4 pF); 1=IPCAP1_100fF (IPCAP1[0] set -> +100 fF); 2=IPCAP1_200fF (IPCAP1[1] set -> +200 fF); 4=IPCAP1_400fF (IPCAP1[2] set -> +400 fF); 8=IPCAP1_80fF (IPCAP1[3] set -> +800 fF); 16=IPCAP1_1600fF (IPCAP1[4] set -> +1600 fF); 32=IPCAP1_3200fF (IPCAP1[5] set -> +3200 fF)
      [21:16] DACCAP — Binary weighted first stage DAC capacitance
        0=DACCAP_min (Min Value = 96 fF); 63=DACCAP_max (Max Value = 6.4 pF); 1=DACCAP_96fF (DACCAP[0] set -> add 12*8= +96 fF); 2=DACCAP_192fF (DACCAP[1] set -> add 24*8= +192 fF); 4=DACCAP_400fF (DACCAP[2] set -> add 50*8= +400 fF); 8=DACCAP_800fF (DACCAP[3] set -> add 100*8= +800 fF); 16=DACCAP_1600fF (DACCAP[4] set -> add 200*8= +1600 fF); 32=DACCAP_3200fF (DACCAP[5] set -> add 400*8= +3200 fF)
      [7:4] SHIFT1 — Value for left shift amount (see SHIFTL in DEC_CTL)
      [2:0] PGA_GAIN — Gain setting of 1,2,4,8,16, 32 are supported
        0=GAIN_1X (1x); 1=GAIN_2X (2x); 2=GAIN_4X (4x); 3=GAIN_8X (8x); 4=GAIN_16X (16x); 5=GAIN_32X (32x)
    0x04 GAIN_CFG1 — Gain configuration register 1
      [23:20] SUMCAPFB — The summer feedback capacitance
        0=SUMCAPFB_50fF (50fF); 1=SUMCAPFB_100fF (100fF); 2=SUMCAPFB_150fF (150fF); 3=SUMCAPFB_200fF (200fF); 4=SUMCAPFB_250fF (250fF); 5=SUMCAPFB_300fF (300fF); 6=SUMCAPFB_350fF (350fF); 7=SUMCAPFB_400fF (400fF); 8=SUMCAPFB_450fF (450fF); 9=SUMCAPFB_500fF (500fF); 10=SUMCAPFB_550fF (550fF); 11=SUMCAPFB_600fF (600fF); 12=SUMCAPFB_650fF (650fF); 13=SUMCAPFB_700fF (700fF); 14=SUMCAPFB_750fF (750fF); 15=SUMCAPFB_800fF (800fF)
      [18:16] SUMCAP3 — The summer capacitance that lies on the feed-forward path from the third integrator output
        0=SUMCAP3_50fF (50fF); 1=SUMCAP3_100fF (100fF); 2=SUMCAP3_150fF (150fF); 3=SUMCAP3_200fF (200fF); 4=SUMCAP3_250fF (250fF); 5=SUMCAP3_300fF (300fF); 6=SUMCAP3_350fF (350fF); 7=SUMCAP3_400fF (400fF)
      [14:12] SUMCAP2 — The summer capacitance that lies on the feed-forward path from the second integrator output
        0=SUMCAP2_50fF (50fF); 1=SUMCAP2_100fF (100fF); 2=SUMCAP2_150fF (150fF); 3=SUMCAP2_200fF (200fF); 4=SUMCAP2_250fF (250fF); 5=SUMCAP2_300fF (300fF); 6=SUMCAP2_350fF (350fF); 7=SUMCAP2_400fF (400fF)
      [10:8] SUMCAP1 — The summer capacitance that lies on the feed-forward path from the first integrator output
        0=SUMCAP1_50fF (50fF); 1=SUMCAP1_100fF (100fF); 2=SUMCAP1_150fF (150fF); 3=SUMCAP1_200fF (200fF); 4=SUMCAP1_250fF (250fF); 5=SUMCAP1_300fF (300fF); 6=SUMCAP1_350fF (350fF); 7=SUMCAP1_400fF (400fF)
      [4:0] SUMCAPIN — The summer capacitance that lies on the path where the input signal is summed
        0=SUMCAPIN_50fF (50fF); 1=SUMCAPIN_100fF (100fF); 2=SUMCAPIN_150fF (150fF); 3=SUMCAPIN_200fF (200fF); 4=SUMCAPIN_250fF (250fF); 5=SUMCAPIN_300fF (300fF); 6=SUMCAPIN_350fF (350fF); 7=SUMCAPIN_400fF (400fF); 8=SUMCAPIN_450fF (450fF); 9=SUMCAPIN_500fF (500fF); 10=SUMCAPIN_550fF (550fF); 11=SUMCAPIN_600fF (600fF); 12=SUMCAPIN_650fF (650fF); 13=SUMCAPIN_700fF (700fF); 14=SUMCAPIN_750fF (750fF); 15=SUMCAPIN_800fF (800fF); 16=SUMCAPIN_850fF (850fF); 17=SUMCAPIN_900fF (900fF); 18=SUMCAPIN_950fF (950fF); 19=SUMCAPIN_1000fF (1000fF); 20=SUMCAPIN_1050fF (1050fF); 21=SUMCAPIN_1100fF (1100fF); 22=SUMCAPIN_1150fF (1150fF); 23=SUMCAPIN_1200fF (1200fF); 24=SUMCAPIN_1250fF (1250fF); 25=SUMCAPIN_1300fF (1300fF); 26=SUMCAPIN_1350fF (1350fF); 27=SUMCAPIN_1400fF (1400fF); 28=SUMCAPIN_1450fF (1450fF); 29=SUMCAPIN_1500fF (1500fF); 30=SUMCAPIN_1550fF (1550fF); 31=SUMCAPIN_1600fF (1600fF)
    0x08 OFST_COR — Offset Correction register
      [15:0] OCOR — Decimator Offset Correction Coefficient See DCHAN.OCOR_COR for description details
    0x0C GAIN_COR — Gain Correction register
      [15:0] GCOR — Decimator Gain Correction Coefficient See DCHAN.GAIN_COR for description details
  0x500 HPBGR_CTL reset 0x200 — High Precision Bandgap Reference Control
    [10:8] HPBGR_FCHOP — High Precision Bandgap Reference Chopping Clock Frequency selection
      values as ACHAN[0].DPATH_CTL.BUF_PGA_FCHOP
    [4] SEL_PHC — Buffer phase compensation option for external capacitor (0: cap present, 1: cap absent)
    [2] CHOP_POS — Chopping position select (0: normal phase, 1: reverse phase. Applies to output buffer and BGR core; BGR core is also affected by CHOP_CLK_SEL). Only applies when CHOP_EN=0.
    [1] CHOP_CLK_SEL — Bgr core chopping phase select input (0: normal phase, 1: reverse phase)
    [0] CHOP_EN — HPBGR Chopping Enable (1: enable, 0: disable) ACHAN0 must be enabled, along with ACHAN0.ACHAN_CTL.MOD_EN for this bit to take affect. Setting this bit also enables a free running clock to the ACHAN0's modulator. This bit should be set to 1 by SW in the default use case.
  0x510 HPBGR_DFT_CTL — High Precision Bandgap Reference DFT Control
    [2:0] ADFT_MODE
  0x600 AREF_CTL — Analog Reference Control
    [0] LP_MODE — Low Power Mode 0 - Full power, all currents available 1 - No 2.4uA currents available, others are available AREF automatically enters low power mode when the device is DeepSleep, this bit can be used to enter low power mode when the device is in Active mode.
  0x610 AREF_DFT_CTL — Analog Reference DFT Control
    [22:20] AREF_SPARE
    [16] DFT_OUT_SEL — ADFT output select (0: to amuxbusa, 1: to amuxbusb)
    [13:12] DFT_RSEL — DFT Resistor Select For applying an internal pulldown resistor on the current output to amuxbus. When the pulldown is activated, both amuxbus_a and amuxbus_b connect to the resistor, allowing for kelvin connection to measure the resistor. 0 - No resistor (current output only) 1 - 10k resistor pulldown 2 - 200k resistor pulldown 3 - 1.2M resistor pulldown
    [11:8] DFT_CURR_SEL — Selects which single current from DFT_SOURCE type to send to ADFT. (0: first current, 1: second current, etc, to max of available currents)
    [4] DFT_SUM — DFT outputs sum (0: Single currents to ADFT, 1: Sum of all currents of type selected by DFT_SOURCE are sent to ADFT)
    [2:0] DFT_SOURCE
  {0x700+0x10*j} OCD_STRUCT[{j}] (j=0..1) group — Over Current Detector Configuration
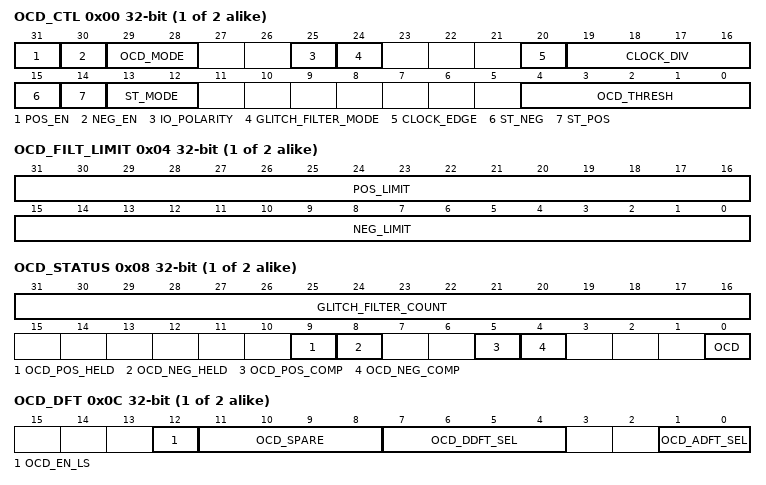
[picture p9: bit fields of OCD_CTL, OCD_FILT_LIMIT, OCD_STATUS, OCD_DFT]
    0x00 OCD_CTL — Over Current Detector Control
      [31] POS_EN — Enable positive comparator
      [30] NEG_EN — Enable negative comparator
      [29:28] OCD_MODE — Selects the output mode. Only exists for OCD0. In any mode other than the default it is used to condense both the OCD1 output and the OCD2 output onto one pin.
        0=Default (OCD0 output pin = OCD0); 1=AND (OCD0 output pin = OCD0 && OCD1); 2=OR (OCD0 output pin = OCD0 || OCD1); 3=RSVD (N/A)
      [25] IO_POLARITY — Selects the assertion polarity of the GPIO OCD output.
        0=ASSERT_LOW (GPIO will be high by default, and assert low during an OCD event); 1=ASSERT_HIGH (GPIO will be low by default, and assert high during an OCD event)
      [24] GLITCH_FILTER_MODE — Selects the operating mode for the glitch filter
        0=CONTINUOUS (In this mode, the positive or negative OCD comparator must be continuously asserted for the number of cycles determined by OCD_FILT.); 1=UP_DN (In this mode, the glitch filter counts away from zero when either OCD comparator is asserted, and back towards zero when both are deasserted.)
      [20] CLOCK_EDGE — Selects which high freq. clock (clk_hf) edge is aligned with OCD clocks
        0=NEG_EDGE (OCD clock aligned with negative high freq. clock (clk_hf) edge); 1=POS_EDGE (OCD clock aligned with positive high freq. clock (clk_hf) edge)
      [19:16] CLOCK_DIV — Uses the dsm clock (clk_dsm) to create OCD clock using the following formula: Focd = Fclk_dsm / (2*(CLOCK_DIV+1))
      [15] ST_NEG — Self Test negative control. Self Test must be enabled for this to have any effect. During Self Test mode controls the negative input to the OCD filter
      [14] ST_POS — Self Test positive control. Self Test must be enabled for this to have any effect. During Self Test mode controls the positive input to the OCD filter
      [13:12] ST_MODE — Self Test mode. Bypasses OCD inputs from hard-ip (pos & neg) with control bits. Disables outputs depending on the mode.
        0=DISABLED (Self Test is disabled); 1=ENABLED_1 (Self Test is enabled. Triggers, interrupts, and outputs are enabled); 2=ENABLED_2 (Self Test is enabled. Triggers, interrupts, and outputs are disabled); 3=RSVD (Self Test is disabled)
      [4:0] OCD_THRESH — Select threshold for overcurrent. Applies to both POS and NEG comparators. There are 3 shunt resistor categories listed below 25uohm shunt resistor case. The thresholds are from 37.5mV = 1500A to 50.0mV = 2000A. 50uohm shunt resistor case. The thresholds are from 75.0mV = 1500A to 100.0mV = 2000A. 100uohm shunt resistor case. The thresholds are from 150.0mV = 1500A to 200.0mV = 2000A.
        0=THRESH_37_5 (37.5 mV); 1=THRESH_40_0 (40.0 mV); 2=THRESH_42_5 (42.5 mV); 3=THRESH_45_0 (45 mV); 4=THRESH_47_5 (47.5 mV); 5=THRESH_50_0 (50 mV); 6=THRESH_50_0A (50 mV); 7=THRESH_50_0B (50 mV); 8=THRESH_75_0 (75 mV); 9=THRESH_80_0 (80 mV); 10=THRESH_85_0 (85 mV); 11=THRESH_90_0 (90 mV); 12=THRESH_95_0 (95 mV); 13=THRESH_100 (100 mV); 14=THRESH_100A (100 mV); 15=THRESH_100B (100 mV); 16=THRESH_150 (150 mV); 17=THRESH_160 (160 mV); 18=THRESH_170 (170 mV); 19=THRESH_180 (180 mV); 20=THRESH_190 (190 mV); 21=THRESH_200 (200 mV); 22=THRESH_200A (200 mV); 23=THRESH_200B (200 mV); 24=THRESH_200C (200 mV)
    0x04 OCD_FILT_LIMIT — Glitch Filter Comparator Settings
      [31:16] POS_LIMIT — Selects the glitch filter counter value limit for the positive OCD. Must be a positive number in twos complement notation. If glitch filter counter = POS_LIMIT, the OCD output will be asserted.
      [15:0] NEG_LIMIT — Selects the glitch filter counter value limit for the negative OCD. Must be a negative number in twos complement notation. If glitch filter counter = NEG_LIMIT, the OCD output will be asserted.
    0x08 OCD_STATUS — Over Current Detector Status
      [31:16] GLITCH_FILTER_COUNT ro — Current state of glitch filter counter
      [9] OCD_POS_HELD write-1-clears — Set if positive OCD comparator has triggered. Clear with write of '1'
      [8] OCD_NEG_HELD write-1-clears — Set if negative OCD comparator has triggered. Clear with write of '1'
      [5] OCD_POS_COMP ro — Current state of positive OCD comparator
      [4] OCD_NEG_COMP ro — Current state of negative OCD comparator
      [0] OCD ro — Current state of glitch filter output
    0x0C OCD_DFT — Over Current Detector DFT Control
      [12] OCD_EN_LS — Enable for OCD level shifter
      [11:8] OCD_SPARE
      [7:4] OCD_DDFT_SEL — OCD DDFT selection 0 - ddft[1] = 0, ddft[0] = 0 1 - ddft[1] = pos_comp_out, ddft[0] = en_pos 2 - ddft[1] = cnt1 , ddft[0] = cnt1 3 - ddft[1] = cnt1 , ddft[0] = cnt1b 4 - ddft[1] = cnt1 , ddft[0] = cnt2 5 - ddft[1] = cnt1 , ddft[0] = cnt3 6 - ddft[1] = ocd_en , ddft[0] = buf_PG 7 - ddft[1] = neg_comp_out , ddft[0] = en_neg 8 - ddft[1] = cnt1 , ddft[0] = buf_PG 9 - ddft[1] = 0, ddft[0] = 0 ..... 15 - ddft[1] = 0, ddft[0] = 0
      [1:0] OCD_ADFT_SEL — OCD ADFT selection if ocd_en = 0, then amuxbus_a = Hi-Z, amuxbus_b = Hi-Z when ocd_en = 1 then sel_adft settings: 0 - amuxbus_a = Hi-Z, amuxbus_b = Hi-Z 1 - amuxbus_a = Hi-Z, amuxbus_b = Hi-Z 2 - amuxbus_a = Reference H output (to measure internal REFH/divout) , amuxbus_b = Reference L output ( to measure internal REFL) 3 - amuxbus_a = Ref amp output , amuxbus_b = Ext. REFH
  0x800 REG_PROT reset 0xF08169E7 — Register Protection
    [31:0] MAGIC — Setting this register to the value 0xf08169e7 unlocks access to Lock Protected Registers. These registers can not be written to unless this value has been written into this register. Writing a value OTHER than the magic key will disable access to the registers. The register POR value is set to 'unlock' the register access.
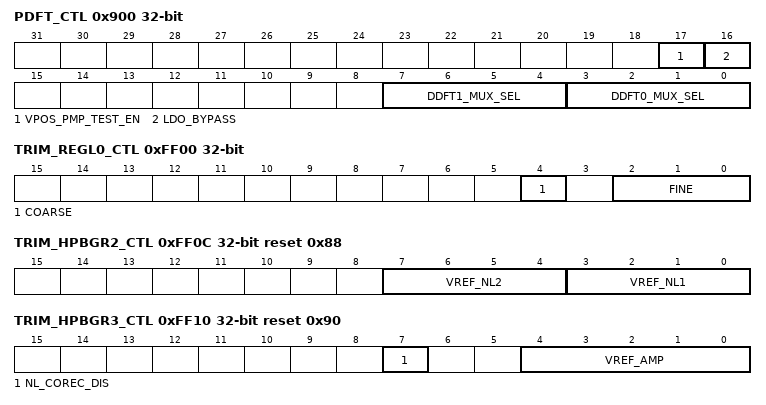
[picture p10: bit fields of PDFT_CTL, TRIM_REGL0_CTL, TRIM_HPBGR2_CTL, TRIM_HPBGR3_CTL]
  0x900 PDFT_CTL — PACSS DFT Control
    [17] VPOS_PMP_TEST_EN — Positive Pump Test Enable
    [16] LDO_BYPASS
    [7:4] DDFT1_MUX_SEL
    [3:0] DDFT0_MUX_SEL
  0xFF00 TRIM_REGL0_CTL — Regulator (LDO) Trim 0 (lock protected)
    [4] COARSE — Coarse Trim
    [2:0] FINE — Fine Trim
  0xFF04 TRIM_HPBGR0_CTL reset 0x80 — High Precision Bandgap Reference Trim Control 0 (lock protected)
    [7:0] VREF_OS — Offset trim for HPBGR 1.2V output
  0xFF08 TRIM_HPBGR1_CTL reset 0x40 — High Precision Bandgap Reference Trim Control 1 (lock protected)
    [6:0] VREF_TC — First order temp-co correction trim
  0xFF0C TRIM_HPBGR2_CTL reset 0x88 — High Precision Bandgap Reference Trim Control 2 (lock protected)
    [7:4] VREF_NL2 — High temperature second order temp-co correction trim
    [3:0] VREF_NL1 — Low temperature second order temp-co correction trim
  0xFF10 TRIM_HPBGR3_CTL reset 0x90 — High Precision Bandgap Reference Trim Control 3 (lock protected)
    [7] NL_COREC_DIS — Second order temp-co correction enable (0: correction, 1: no correction)
    [4:0] VREF_AMP — Chopping amplifier trim
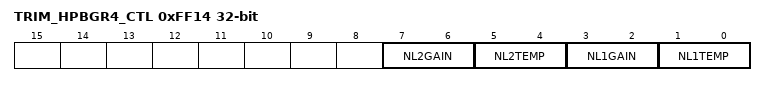
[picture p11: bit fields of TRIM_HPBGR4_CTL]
  0xFF14 TRIM_HPBGR4_CTL — High Precision Bandgap Reference Trim Control 4 (lock protected)
    [7:6] NL2GAIN — Non-linearity Gain Trim 2
    [5:4] NL2TEMP — Non-linearity Temperature Trim 2
    [3:2] NL1GAIN — Non-linearity Gain Trim 1
    [1:0] NL1TEMP — Non-linearity Temperature Trim 1
  0xFF18 TRIM_AREF0_CTL — Analog Reference Trim Control 0 (lock protected)
    [4:0] ICTAT — Trim for AREF CTAT currents
  0xFF1C TRIM_AREF1_CTL — Analog Reference Trim Control 1 (lock protected)
    [3:0] IPTAT_COARSE — Coarse Trim for AREF PTAT currents
  0xFF20 TRIM_AREF2_CTL — Analog Reference Trim Control 2 (lock protected)
    [4:0] IPTAT_FINE — Fine Trim for AREF PTAT currents
  0xFF24 TRIM_AREF3_CTL — Analog Reference Trim Control 3 (lock protected)
    [2:0] PTAT_DAC — Trim for AREF PTAT DAC
  0xFF28 TRIM_AREF4_CTL — Analog Reference Trim Control 4 (lock protected)
    [3:0] ZTAT_COARSE — Coarse Trim for AREF ZTAT
  0xFF2C TRIM_AREF5_CTL — Analog Reference Trim Control 5 (lock protected)
    [4:0] ZTAT_FINE — Fine Trim for AREF ZTAT Only bits [3:0] are functional. Bit 4 is a spare bit.
  0xFF30 TRIM_AREF6_CTL — Analog Reference Trim Control 6 (lock protected)
    [3:0] CTAT_COARSE — Coarse Trim for AREF CTAT
  0xFF34 TRIM_OCD00_CTL — Trim Control 0 for Over Current Detector 0 (lock protected)
    [7:0] TRIM0
  0xFF38 TRIM_OCD01_CTL — Trim Control 0 for Over Current Detector 1 (lock protected)
    [7:0] TRIM1
  0xFF3C TRIM_OCD10_CTL — Trim Control 1 for Over Current Detector 0 (lock protected))
    [7:0] TRIM0
  0xFF40 TRIM_OCD11_CTL — Trim Control 1 for Over Current Detector 1 (lock protected)
    [7:0] TRIM1
